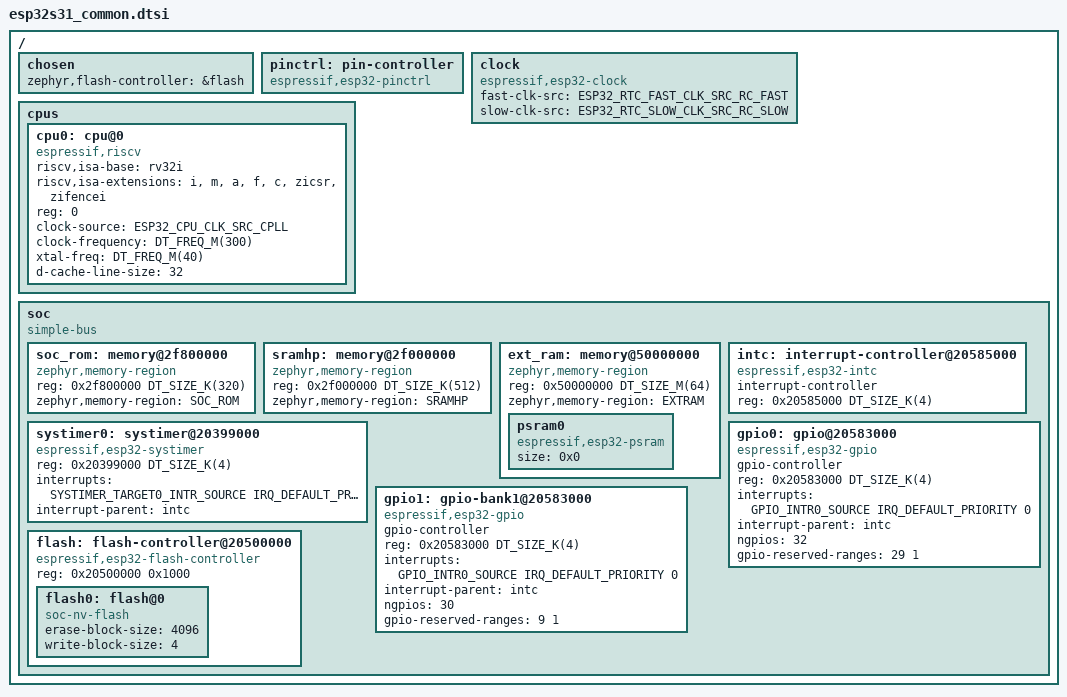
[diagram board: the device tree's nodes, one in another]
/*
 * Copyright (c) 2026 Espressif Systems (Shanghai) Co., Ltd.
 *
 * SPDX-License-Identifier: Apache-2.0
 */
#include <mem.h>
#include <freq.h>
#include <zephyr/dt-bindings/gpio/gpio.h>
#include <zephyr/dt-bindings/interrupt-controller/esp-esp32s31-intmux.h>
#include <zephyr/dt-bindings/clock/esp32s31_clock.h>
#include <zephyr/dt-bindings/memory-attr/memory-attr-riscv.h>

/*
 * This initial devicetree only covers what's needed to elaborate the SoC
 * init/linker files already added to this port (soc_rom / sramhp / ext_ram
 * are referenced by memory.h and pmp_regions.c) plus the interrupt
 * controller and systimer needed for the kernel tick. UART, GPIO, and
 * other peripherals are intentionally left out: they need a pinctrl
 * devicetree binding (mechanically derivable from hal_espressif's
 * gpio_sig_map.h, not yet generated) and, for peripherals without a
 * shared_periph_module_t entry, PCR (peripheral clock/reset) per-bit
 * clock-gate assignments this port hasn't cross-checked yet.
 */

/ {
	#address-cells = <1>;
	#size-cells = <1>;

	chosen {
		zephyr,flash-controller = &flash;
	};

	pinctrl: pin-controller {
		compatible = "espressif,esp32-pinctrl";
		status = "okay";
	};

	/* fast/slow-clk-src default to the internal RC oscillators (no
	 * external 32kHz crystal assumed), same default as every other
	 * Espressif Zephyr target. Values from esp32s31_clock.h, which are
	 * this chip's own confirmed soc_rtc_fast_clk_src_t/
	 * soc_rtc_slow_clk_src_t enums (ESP32-S31 has fewer source options
	 * than e.g. ESP32-C61 -- see that header for specifics).
	 */
	clock: clock {
		compatible = "espressif,esp32-clock";
		fast-clk-src = <ESP32_RTC_FAST_CLK_SRC_RC_FAST>;
		slow-clk-src = <ESP32_RTC_SLOW_CLK_SRC_RC_SLOW>;
		#clock-cells = <1>;
		status = "okay";
	};

	cpus {
		#address-cells = <1>;
		#size-cells = <0>;

		/* ESP32-S31 is dual-core (plus an LP RISC-V co-processor); this
		 * initial port only brings up the main core and has no SMP
		 * support yet, so only cpu@0 is declared. hal_espressif's
		 * soc.h documents interrupt number 24-28 as reserved for
		 * riscv/vector_clic.S; the CLIC line count (48 total, 16
		 * internal + 32 external) is confirmed by clic_reg.h's
		 * CLIC_INT_INFO_NUM_INT reset value.
		 *
		 * d-cache-line-size is carried over from ESP32-C61 (same CLIC
		 * generation) as a starting point; it has not been
		 * independently confirmed for ESP32-S31 and should be checked
		 * once cache HAL details are cross-referenced.
		 *
		 * riscv,isa-extensions includes "f": confirmed via two
		 * independent sources, not assumed. hal_espressif's real
		 * esp32s31 soc_caps.h declares SOC_CPU_HAS_FPU=1 (single-
		 * precision only -- no SOC_CPU_HAS_FPU_DOUBLE_PRECISION-style
		 * macro, matching the "single-float ABI" flag on prebuilt
		 * ESP32-S31 BT controller blobs from espressif/esp32s31-bt-lib,
		 * whose object files were independently confirmed by
		 * disassembly to execute real F-extension instructions
		 * (fcvt.s.w, fmul.s, feq.s), not just carry an unused ABI tag.
		 *
		 * hal_espressif's soc_caps.h also documents a real errata,
		 * SOC_CPU_HAS_FPU_EXT_ILL_BUG ("EXT_ILL CSR doesn't support
		 * FLW/FSW"): the trap this chip would need for Zephyr's lazy/
		 * shared FPU context-switching (CONFIG_FPU_SHARING) to detect
		 * first FPU use doesn't fire for float load/store, only for
		 * compute instructions. A thread's first FPU access via FLW
		 * would silently miss the trap and could see another thread's
		 * stale FPU register contents. Do not enable CONFIG_FPU_SHARING
		 * for this chip without addressing that gap; CONFIG_FPU without
		 * sharing (always save/restore FPU context on switch) has no
		 * such issue since it never depends on catching first use.
		 */
		cpu0: cpu@0 {
			device_type = "cpu";
			compatible = "espressif,riscv", "riscv";
			riscv,isa-base = "rv32i";
			riscv,isa-extensions = "i", "m", "a", "f", "c", "zicsr", "zifencei";
			reg = <0>;
			clock-source = <ESP32_CPU_CLK_SRC_CPLL>;
			/* hal_espressif's soc_cpu_clk_src_t CPLL comment describes the
			 * CPLL circuit as capable of up to 320MHz; esptool's own chip
			 * database (confirmed against real ESP32-S31-Korvo-1 hardware)
			 * reports a rated 300MHz. Using the confirmed-on-hardware
			 * value here; the exact supported discrete CPU frequency set
			 * (as validated by hal_espressif's rtc_clk_cpu_freq_mhz_to_config)
			 * is not yet cross-checked.
			 */
			clock-frequency = <DT_FREQ_M(300)>;
			xtal-freq = <DT_FREQ_M(40)>;
			d-cache-line-size = <32>;
		};
	};

	soc {
		#address-cells = <1>;
		#size-cells = <1>;
		compatible = "simple-bus";
		ranges;

		/* ROM code region (libc and utility functions).
		 * hal_espressif soc.h: SOC_IROM_MASK_LOW/HIGH = 0x2F800000 / 0x2F850000 (320KB).
		 */
		soc_rom: memory@2f800000 {
			compatible = "zephyr,memory-region";
			reg = <0x2f800000 DT_SIZE_K(320)>;
			zephyr,memory-region = "SOC_ROM";
		};

		/* HP-SRAM, unified I/D address space.
		 * hal_espressif soc.h: SOC_IRAM_LOW/HIGH == SOC_DRAM_LOW/HIGH
		 * = 0x2F000000 / 0x2F080000 (512KB).
		 */
		sramhp: memory@2f000000 {
			compatible = "zephyr,memory-region", "mmio-sram";
			reg = <0x2f000000 DT_SIZE_K(512)>;
			zephyr,memory-region = "SRAMHP";
		};

		/* PSRAM cache window.
		 * hal_espressif soc.h: SOC_EXTRAM_LOW/HIGH = 0x50000000 / 0x54000000 (64MB).
		 */
		ext_ram: memory@50000000 {
			compatible = "zephyr,memory-region";
			reg = <0x50000000 DT_SIZE_M(64)>;
			zephyr,memory-region = "EXTRAM";

			psram0: psram0 {
				compatible = "espressif,esp32-psram";
				size = <0x0>;
			};
		};

		/* Interrupt matrix / router, in front of each core's CLIC.
		 * hal_espressif reg_base.h: DR_REG_INTERRUPT_MATRIX_BASE ==
		 * DR_REG_INTERRUPT_CORE0_BASE == DR_REG_INTR0_BASE = 0x20585000
		 * (core1's window is DR_REG_INTERRUPT_CORE1_BASE, +0x800, not
		 * yet used since this port has no SMP support).
		 */
		intc: interrupt-controller@20585000 {
			compatible = "espressif,esp32-intc";
			#address-cells = <0>;
			#interrupt-cells = <3>;
			interrupt-controller;
			reg = <0x20585000 DT_SIZE_K(4)>;
			status = "okay";
		};

		/* hal_espressif reg_base.h: DR_REG_SYSTIMER_BASE = 0x20399000. */
		systimer0: systimer@20399000 {
			compatible = "espressif,esp32-systimer";
			reg = <0x20399000 DT_SIZE_K(4)>;
			interrupts = <SYSTIMER_TARGET0_INTR_SOURCE IRQ_DEFAULT_PRIORITY 0>;
			interrupt-parent = <&intc>;
			status = "okay";
		};

		/* GPIO controllers. hal_espressif reg_base.h:
		 * DR_REG_GPIO_BASE = 0x20583000; soc_caps.h:
		 * SOC_GPIO_PIN_COUNT = 62 (0..61), with pins 29 and 41
		 * excluded from SOC_GPIO_VALID_GPIO_MASK (reserved for
		 * internal use) -- reflected below as gpio-reserved-ranges,
		 * bank-relative per the binding (pin 41 is index 9 within
		 * gpio1's 32..61 range).
		 *
		 * Unlike chips with two genuinely separate GPIO register
		 * blocks 0x800 apart (e.g. ESP32-S3, -P4), ESP32-S31's real
		 * gpio_reg.h has GPIO_OUT1_REG at only GPIO_BASE + 0x10 --
		 * one tightly-packed gpio_dev_t struct covering both pin
		 * banks (confirmed the same on ESP32-C5, this chip's
		 * closest architectural sibling with the same register
		 * generation). drivers/gpio/gpio_esp32.c's
		 * ESP_SOC_GPIO_INIT casts each instance's own
		 * DT_REG_ADDR(gpio##_id) to gpio_dev_t* and accesses
		 * ->out1/->out1_w1ts/etc as plain struct members (compiler-
		 * computed offsets) -- so gpio1's reg must be the SAME base
		 * address as gpio0, not base+0x800, for ->out1_w1ts to
		 * resolve to the real GPIO_OUT1_W1TS_REG address. Both
		 * nodes share the same core-0 GPIO interrupt source
		 * (GPIO_INTR0_SOURCE); this chip has 4 total
		 * (GPIO_INTR0..3_SOURCE, likely one pair per core), but
		 * this port has no SMP support yet so only core 0's is
		 * used.
		 */
		gpio0: gpio@20583000 {
			compatible = "espressif,esp32-gpio";
			gpio-controller;
			#gpio-cells = <2>;
			reg = <0x20583000 DT_SIZE_K(4)>;
			interrupts = <GPIO_INTR0_SOURCE IRQ_DEFAULT_PRIORITY 0>;
			interrupt-parent = <&intc>;
			ngpios = <32>;
			gpio-reserved-ranges = <29 1>;
			status = "okay";
		};

		gpio1: gpio-bank1@20583000 {
			compatible = "espressif,esp32-gpio";
			gpio-controller;
			#gpio-cells = <2>;
			reg = <0x20583000 DT_SIZE_K(4)>;
			interrupts = <GPIO_INTR0_SOURCE IRQ_DEFAULT_PRIORITY 0>;
			interrupt-parent = <&intc>;
			ngpios = <30>;
			gpio-reserved-ranges = <9 1>;
			status = "okay";
		};

		/* Flash controller node: reg/ranges filled in by the flash
		 * variant dtsi (see e.g. esp32s31_korvo_1 board devicetree,
		 * once added) the same way ESP32-C61's wroom_n8[.r2].dtsi do.
		 * hal_espressif reg_base.h: DR_REG_FLASH_SPI0_BASE = 0x20500000.
		 */
		flash: flash-controller@20500000 {
			compatible = "espressif,esp32-flash-controller";
			reg = <0x20500000 0x1000>;

			#address-cells = <1>;
			#size-cells = <1>;
			ranges;

			flash0: flash@0 {
				compatible = "soc-nv-flash";
				erase-block-size = <4096>;
				write-block-size = <4>;
				#address-cells = <1>;
				#size-cells = <1>;
				/* reg and ranges are specified in SOC/SIP dtsi */
			};
		};
	};
};
